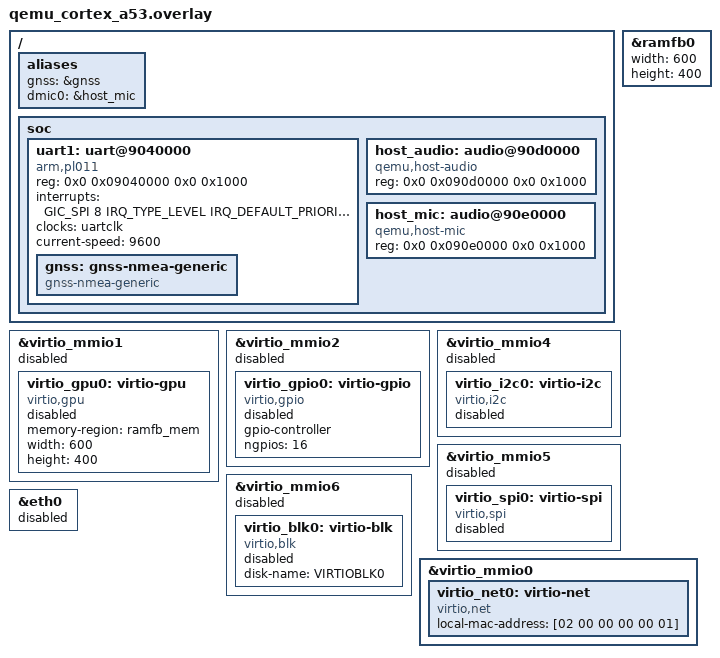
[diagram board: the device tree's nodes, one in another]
/*
 * Copyright (c) 2026
 * SPDX-License-Identifier: Apache-2.0
 *
 * Browser bridge on the Cortex-A53 (virt) machine: the browser-fed GNSS UART
 * on virt's spare PL011 slot, a browser-sized ramfb, and the host audio/mic
 * bridges. Sensors are no longer here — they are simulated I2C parts on the
 * virtio-i2c bus (tmp112/lm75/adxl345), and the accel0 alias for the LVGL
 * accelerometer chart lives in that snippet, not this shield.
 *
 * The host audio out sits at 0x090d0000 and the host microphone at 0x090e0000
 * — holes in virt's MMIO map between the secure GPIO (0x090b0000) and the
 * virtio region (0x0a000000), so they cannot collide with anything the machine
 * actually maps. Our patched qemu-wasm virt machine instantiates the devices at
 * these exact addresses; see tools/qemu-jit-patches/0005-hw-misc-add-qemu-host-
 * audio.patch and 0006-hw-misc-add-qemu-host-mic.patch. The qemu,host-sensor
 * device that used to sit at 0x090c0000 is gone from the emulator — its patch
 * was dropped once nothing bound it.
 *
 * Zephyr's stock Cortex-A53 ramfb is 1024x768. That is unnecessarily large for
 * the browser demo: every refresh is emulated by QEMU and uploaded as a browser
 * texture. 600x400 retains a useful 3:2 display while reducing the pixel count
 * by 69.5%.
 */

/ {
	aliases {
		gnss = &gnss;
		dmic0 = &host_mic;
	};

	soc {
		uart1: uart@9040000 {
			compatible = "arm,pl011";
			reg = <0x0 0x09040000 0x0 0x1000>;
			interrupts = <GIC_SPI 8 IRQ_TYPE_LEVEL IRQ_DEFAULT_PRIORITY>;
			interrupt-names = "irq_0";
			clocks = <&uartclk>;
			current-speed = <9600>;
			status = "okay";

			gnss: gnss-nmea-generic {
				compatible = "gnss-nmea-generic";
			};
		};

		host_audio: audio@90d0000 {
			compatible = "qemu,host-audio";
			reg = <0x0 0x090d0000 0x0 0x1000>;
			status = "okay";
		};

		host_mic: audio@90e0000 {
			compatible = "qemu,host-mic";
			reg = <0x0 0x090e0000 0x0 0x1000>;
			status = "okay";
		};
	};
};

&ramfb0 {
	width = <600>;
	height = <400>;
};

/*
 * The same panel behind a virtio-gpu instead of ramfb, declared here but left
 * disabled: `-S virtio-gpu` (zephyr-module/snippets/virtio-gpu/) is what turns
 * it on and repoints zephyr,display at it. Declaring it unconditionally costs a
 * disabled node and nothing else — no driver is built unless the snippet runs.
 *
 * Slot 1 of virt's virtio-mmio array (0x0a000200, SPI 17), which QEMU populates
 * with `-device virtio-gpu-device,bus=virtio-mmio-bus.1`; slot 0 is virtio-net.
 * Its xres/yres must equal the width/height below — the driver refuses to
 * attach to a scanout whose size differs from devicetree — and both must match
 * the args in src/boards.ts.
 *
 * The framebuffer deliberately shares ramfb's reserved region: the two displays
 * are mutually exclusive (the snippet disables one to enable the other), so a
 * second 4 MiB carve-out of sram0 would only ever sit idle.
 */
&virtio_mmio1 {
	status = "disabled";

	virtio_gpu0: virtio-gpu {
		compatible = "virtio,gpu";
		memory-region = <&ramfb_mem>;
		width = <600>;
		height = <400>;
		status = "disabled";
	};
};

/*
 * Browser GPIO bridge: a standard VIRTIO GPIO device (virtio spec 1.3, section
 * 5.16) on slot 2 of virt's virtio-mmio array (0x0a000400, SPI 18), which QEMU
 * populates with `-device virtio-browser-device,...,name=gpio,device-id=41`.
 * Slots 0, 1 and 3 are virtio-net, virtio-gpu and the tablet.
 *
 * Unlike the Cortex-M3's qemu,host-gpio — a bespoke register block behind a
 * bespoke driver — the guest side here is a stock VIRTIO driver. The QEMU side
 * still is not stock: hw/virtio/ ships only vhost-user-gpio, which forwards the
 * virtqueues to a separate daemon, and a wasm build in a tab has no second
 * process to run one in. What backs this is the *generic* browser virtio bridge
 * (tools/qemu-jit-patches/0010-hw-virtio-add-generic-browser-virtio-bridge.patch),
 * which carries whole virtqueue chains out to the page — the GPIO device model
 * itself is TypeScript, in src/virtio/devices/gpio.ts. See docs/virtio-bridge.md.
 *
 * Declared disabled, like virtio_gpu0 above: `-S virtio-gpio`
 * (zephyr-module/snippets/virtio-gpio/) is what turns it on and adds the LED
 * and button nodes wired to it. ngpios must match the ngpio the device's
 * `config=` property advertises, in src/boards.ts.
 */
&virtio_mmio2 {
	status = "disabled";

	virtio_gpio0: virtio-gpio {
		compatible = "virtio,gpio";
		gpio-controller;
		#gpio-cells = <2>;
		ngpios = <16>;
		status = "disabled";
	};
};

/*
 * Browser I2C bridge: a VIRTIO I2C adapter (virtio spec 1.3, section 5.15) on
 * slot 4 of virt's virtio-mmio array (0x0a000800, SPI 20), which QEMU populates
 * with `-device virtio-browser-device,...,name=i2c,device-id=34`. Slots 0-3 are
 * virtio-net, virtio-gpu, the GPIO controller and the tablet.
 *
 * The adapter is the same generic bridge the GPIO controller uses — one C file
 * in QEMU, no device model of its own. What is new is the guest side: Zephyr
 * has no virtio I2C driver, so this repo carries one at
 * zephyr-module/drivers/i2c_virtio.c, written to go upstream.
 *
 * The chips on the bus are page-side models under src/virtio/devices/chips/,
 * so what a build sees here is whatever the page has attached — an address
 * with nothing behind it NAKs, which is what makes `i2c scan` a real scan.
 *
 * Declared disabled, like virtio_gpio0 above: `-S virtio-i2c`
 * (zephyr-module/snippets/virtio-i2c/) turns it on and adds the chip nodes.
 */
&virtio_mmio4 {
	status = "disabled";

	virtio_i2c0: virtio-i2c {
		compatible = "virtio,i2c";
		#address-cells = <1>;
		#size-cells = <0>;
		status = "disabled";
	};
};

/*
 * Browser SPI bridge: a VIRTIO SPI controller (device id 45) on slot 5 of
 * virt's virtio-mmio array (0x0a000a00, SPI 21), which QEMU populates with
 * `-device virtio-browser-device,...,name=spi,device-id=45`. Slots 0-4 are
 * virtio-net, virtio-gpu, GPIO, tablet and I2C.
 *
 * Same generic bridge as GPIO and I2C. The guest driver is vendored from
 * kartben/zephyr#469 (zephyr-module/drivers/vendor/spi_virtio.c) until it
 * lands upstream. Chips on the bus are page-side models under
 * src/virtio/devices/; chip select is the child's `reg`.
 *
 * Declared disabled: `-S virtio-spi` turns it on and adds the flash node.
 */
&virtio_mmio5 {
	status = "disabled";

	virtio_spi0: virtio-spi {
		compatible = "virtio,spi";
		#address-cells = <1>;
		#size-cells = <0>;
		status = "disabled";
	};
};

/*
 * Block device: a VIRTIO block device on slot 6 of virt's virtio-mmio array
 * (0x0a000c00, SPI 22). Slots 0-5 are virtio-net, virtio-gpu, GPIO, tablet,
 * I2C and SPI.
 *
 * This one is the odd one out. Every other virtio device on this shield is the
 * generic browser bridge with a TypeScript device model behind it, because QEMU
 * ships no model we can use in a single-process wasm build. virtio-blk it does
 * ship — `virtio-blk-device` and the whole block layer are already linked into
 * the packaged emulators — so there is no page-side model and no QEMU patch
 * here at all. The backing store is a raw image the page allocates in the
 * Emscripten filesystem; see the `virtio_blk` sample in src/boards.ts, whose
 * `extraArgs` attach `-drive` + `-device virtio-blk-device` for that sample
 * alone. A disk is not free the way the other bridges are, which is why it is
 * per-sample rather than in the board argv.
 *
 * The guest driver is vendored from zephyrproject-rtos/zephyr#112581
 * (zephyr-module/drivers/vendor/virtio_blk.c) until it lands upstream.
 *
 * Declared disabled: `-S virtio-blk` turns it on and adds the FAT mount.
 */
&virtio_mmio6 {
	status = "disabled";

	virtio_blk0: virtio-blk {
		compatible = "virtio,blk";
		disk-name = "VIRTIOBLK0";
		status = "disabled";
	};
};

/*
 * Browser network bridge: virtio-net on the first virtio-mmio slot, which
 * QEMU populates with `-device virtio-net-device,bus=virtio-mmio-bus.0`
 * (0x0a000000, SPI 16). The MAC must stay in step with the `mac=` property
 * in src/boards.ts: QEMU's virtio-net model filters inbound unicast against
 * it, and Zephyr's driver takes its address from devicetree without ever
 * programming the device. Costs non-networking samples nothing — the driver
 * stack only builds behind NET_L2_ETHERNET.
 */
&virtio_mmio0 {
	status = "okay";

	virtio_net0: virtio-net {
		compatible = "virtio,net";
		local-mac-address = [02 00 00 00 00 01];
		status = "okay";
	};
};

/*
 * Silence the stock e1000 PCIe path: the promptless QEMU_CORTEX_A53_ETH_E1000
 * would otherwise select ETH_E1000 + PCIE (with a 2 GiB VM space) the moment
 * NETWORKING=y, fighting the virtio-net setup above.
 */
&eth0 {
	status = "disabled";
};
